# STM32F098xx register map
File version: 1.0
Registers are 32-bit, read-write, reset 0x0 unless marked. A register's access mark holds for its fields unless they carry their own. Offsets are from the block's base; [hi:lo] are bit positions; {n}, {i} and the like mark numbered series.

## OB — Option Bytes Registers
Base 0x1FFFF800
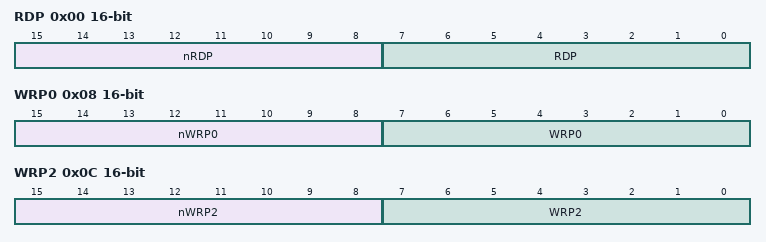
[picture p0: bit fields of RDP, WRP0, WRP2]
0x00 RDP 16-bit — FLASH option byte Read protection
  [15:8] nRDP — Read protection complemented option byte
  [7:0] RDP — Read protection option byte
0x02 USER 16-bit — FLASH option byte user options
  [31:24] nUSER — User complemented option byte
  [23:16] USER — User option byte
0x04 DATA0 16-bit — User data byte 0 (stored in FLASH_OBR[23:16])
0x06 DATA1 16-bit — User data byte 1 (stored in FLASH_OBR[31:24])
0x08 WRP0 16-bit — FLASH option byte write protection 0
  [15:8] nWRP0 — Flash memory write protection complemented option bytes
  [7:0] WRP0 — Flash memory write protection option bytes
0x0A WRP1 16-bit — FLASH option byte write protection 1
  [31:24] nWRP1 — Flash memory write protection complemented option bytes
  [23:16] WRP1 — Flash memory write protection option bytes
0x0C WRP2 16-bit — FLASH option byte write protection 2
  [15:8] nWRP2 — Flash memory write protection complemented option bytes
  [7:0] WRP2 — Flash memory write protection option bytes
0x0E WRP3 16-bit — FLASH option byte write protection 3
  [31:24] nWRP3 — Flash memory write protection complemented option bytes
  [23:16] WRP3 — Flash memory write protection option bytes

## TIM6 — TIM
Base 0x40001000
Same registers: TIM7 0x40001400
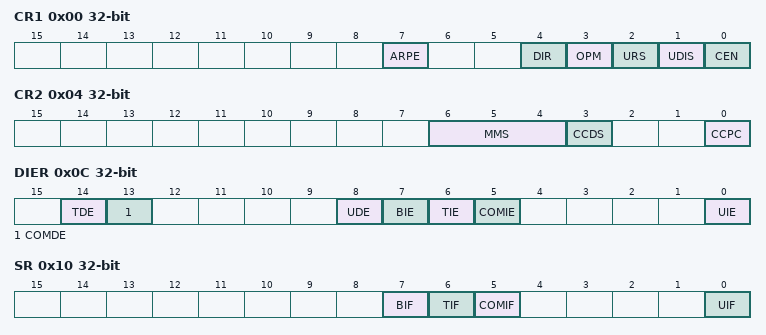
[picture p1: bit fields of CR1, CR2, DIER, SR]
0x00 CR1 — TIM control register 1
  [7] ARPE — Auto-reload preload enable
  [4] DIR — Direction
    0=UP (Timer counter counts up); 1=DOWN (Timer counter counts down)
  [3] OPM — One pulse mode
    1=SINGLE (Counter stops counting at the next update event); 0=REPETITIVE (Counter is not stopped at update event)
  [2] URS — Update request source
    0=REGULAR (Counter overflow/underflow, Setting the UG bit or Update generation through the slave mode controller generates an update request); 1=COUNTER (Only counter overflow/underflow generates an update request)
  [1] UDIS — Update disable
  [0] CEN — Counter enable
0x04 CR2 — TIM control register 2
  [6:4] MMS — MMS[2:0] bits (Master Mode Selection)
    0=RESET (UG bit from the TIMx_EGR register is used as trigger output); 1=ENABLE (Counter Enable signal (CNT_EN) is used as trigger output); 2=UPDATE (Update event is used as trigger output); 3=CC1IF (CC1 capture or a compare match is used as trigger output); {v}=OC{v-3}REF (OC{v-3}REF signal is used as trigger output) (v=4..7)
  [3] CCDS — Capture/Compare DMA Selection
    0=CC (CCx DMA request sent when CCx event occurs); 1=UPDATE (CCx DMA requests sent when update event occurs)
  [0] CCPC — Capture/Compare Preloaded Control
0x08 SMCR — TIM slave Mode Control register
  [3] OCCS — OCREF clear selection
    0=OCREF_CLR (OCREF_CLR_INT is connected to the OCREF_CLR input); 1=ETR (OCREF_CLR_INT is connected to ETRF)
0x0C DIER — TIM DMA/interrupt enable register
  [14] TDE — Trigger DMA request enable
  [13] COMDE — COM DMA request enable
  [8] UDE — Update DMA request enable
  [7] BIE — Break interrupt enable
  [6] TIE — Trigger interrupt enable
  [5] COMIE — COM interrupt enable
  [0] UIE — Update interrupt enable
0x10 SR — TIM status register
  [7] BIF — Break interrupt Flag
  [6] TIF — Trigger interrupt Flag
  [5] COMIF — COM interrupt Flag
  [0] UIF — Update interrupt Flag
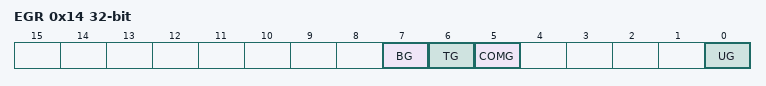
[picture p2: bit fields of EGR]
0x14 EGR — TIM event generation register
  [7] BG — Break Generation
  [6] TG — Trigger Generation
  [5] COMG — Capture/Compare Control Update Generation
  [0] UG — Update Generation
0x24 CNT — TIM counter register
  [15:0] CNT — Counter Value
0x28 PSC — TIM prescaler register
  [15:0] PSC — Prescaler Value
0x2C ARR — TIM auto-reload register
  [15:0] ARR — actual auto-reload Value
0x4C DMAR — TIM DMA address for full transfer register
  [15:0] DMAB — DMA register for burst accesses
0x50 OR — TIM option register
